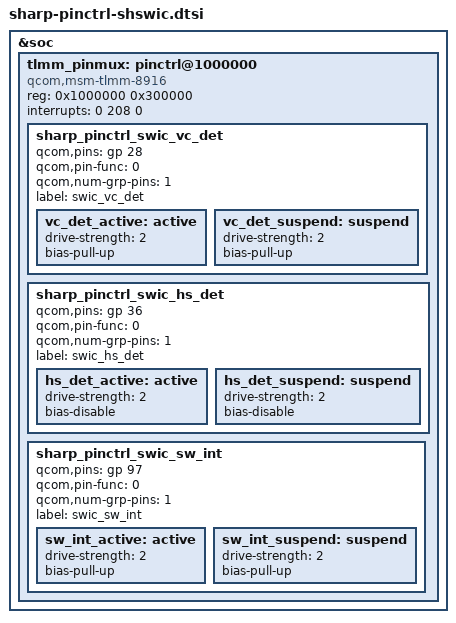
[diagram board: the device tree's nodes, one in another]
/* Copyright (c) 2013-2014, The Linux Foundation. All rights reserved.
 *
 * This program is free software; you can redistribute it and/or modify
 * it under the terms of the GNU General Public License version 2 and
 * only version 2 as published by the Free Software Foundation.
 *
 * This program is distributed in the hope that it will be useful,
 * but WITHOUT ANY WARRANTY; without even the implied warranty of
 * MERCHANTABILITY or FITNESS FOR A PARTICULAR PURPOSE.  See the
 * GNU General Public License for more details.
 */

&soc {
	tlmm_pinmux: pinctrl@1000000 {
		compatible = "qcom,msm-tlmm-8916";
		reg = <0x1000000 0x300000>;
		interrupts = <0 208 0>;
		/*****************************************/
		/*  pinctrl customize setting            */
		/*****************************************/
		sharp_pinctrl_swic_vc_det{
			qcom,pins = <&gp 28>;
			qcom,pin-func = <0>;
			qcom,num-grp-pins = <1>;
			label = "swic_vc_det";
			vc_det_active: active {
				drive-strength = <2>;
				bias-pull-up;
			};
			vc_det_suspend: suspend {
				drive-strength = <2>;
				bias-pull-up;
			};
		};
		sharp_pinctrl_swic_hs_det{
			qcom,pins = <&gp 36>;
			qcom,pin-func = <0>;
			qcom,num-grp-pins = <1>;
			label = "swic_hs_det";
			hs_det_active: active {
				drive-strength = <2>;
				bias-disable;
			};
			hs_det_suspend: suspend {
				drive-strength = <2>;
				bias-disable;
			};
		};
		sharp_pinctrl_swic_sw_int{
			qcom,pins = <&gp 97>;
			qcom,pin-func = <0>;
			qcom,num-grp-pins = <1>;
			label = "swic_sw_int";
			sw_int_active: active {
				drive-strength = <2>;
				bias-pull-up;
			};
			sw_int_suspend: suspend {
				drive-strength = <2>;
				bias-pull-up;
			};
		};
	};
};
